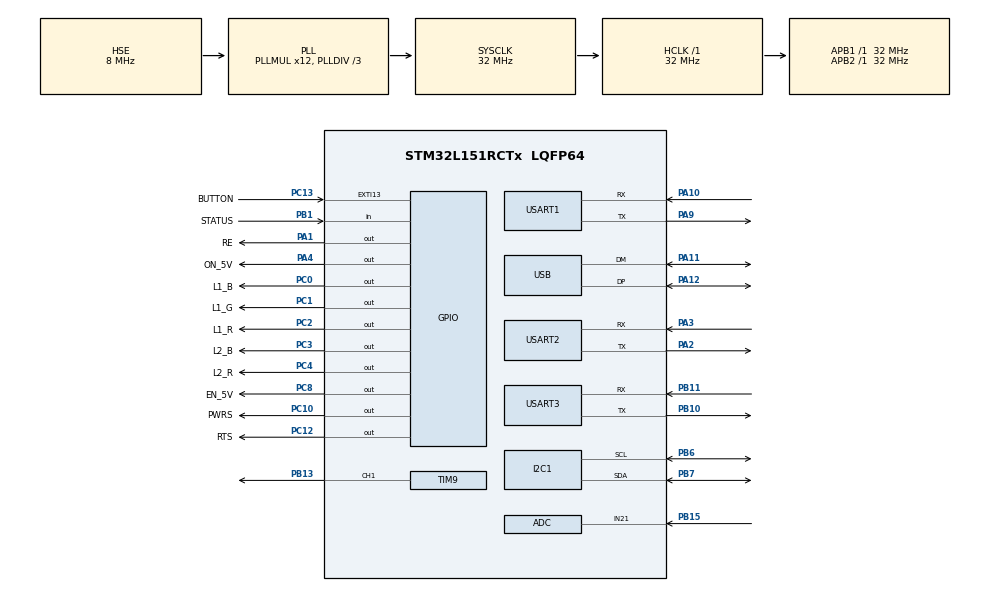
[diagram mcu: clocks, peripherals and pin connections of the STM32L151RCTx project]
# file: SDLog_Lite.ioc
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ADC.Channel-0\#ChannelRegularConversion=ADC_CHANNEL_21
ADC.NbrOfConversionFlag=1
ADC.Rank-0\#ChannelRegularConversion=1
ADC.SamplingTime-0\#ChannelRegularConversion=ADC_SAMPLETIME_4CYCLES
Dma.Request0=USART2_RX
Dma.Request1=USART3_RX
Dma.Request2=USART1_RX
Dma.USART1_RX.2.Direction=DMA_PERIPH_TO_MEMORY
Dma.USART1_RX.2.Instance=DMA1_Channel5
Dma.USART1_RX.2.MemDataAlignment=DMA_MDATAALIGN_BYTE
Dma.USART1_RX.2.MemInc=DMA_MINC_ENABLE
Dma.USART1_RX.2.Mode=DMA_NORMAL
Dma.USART1_RX.2.PeriphDataAlignment=DMA_PDATAALIGN_BYTE
Dma.USART1_RX.2.PeriphInc=DMA_PINC_DISABLE
Dma.USART1_RX.2.Priority=DMA_PRIORITY_LOW
Dma.USART2_RX.0.Direction=DMA_PERIPH_TO_MEMORY
Dma.USART2_RX.0.Instance=DMA1_Channel6
Dma.USART2_RX.0.MemDataAlignment=DMA_MDATAALIGN_BYTE
Dma.USART2_RX.0.MemInc=DMA_MINC_ENABLE
Dma.USART2_RX.0.Mode=DMA_NORMAL
Dma.USART2_RX.0.PeriphDataAlignment=DMA_PDATAALIGN_BYTE
Dma.USART2_RX.0.PeriphInc=DMA_PINC_DISABLE
Dma.USART2_RX.0.Priority=DMA_PRIORITY_LOW
Dma.USART3_RX.1.Direction=DMA_PERIPH_TO_MEMORY
Dma.USART3_RX.1.Instance=DMA1_Channel3
Dma.USART3_RX.1.MemDataAlignment=DMA_MDATAALIGN_BYTE
Dma.USART3_RX.1.MemInc=DMA_MINC_ENABLE
Dma.USART3_RX.1.Mode=DMA_NORMAL
Dma.USART3_RX.1.PeriphDataAlignment=DMA_PDATAALIGN_BYTE
Dma.USART3_RX.1.PeriphInc=DMA_PINC_DISABLE
Dma.USART3_RX.1.Priority=DMA_PRIORITY_LOW
Mcu.Family=STM32L1
Mcu.Name=STM32L151RCTx
Mcu.Package=LQFP64
NVIC.DMA1_Channel3_IRQn=true\:0\:0\:false\:false\:true\:false\:true\:true
NVIC.DMA1_Channel5_IRQn=true\:0\:0\:false\:false\:true\:false\:true\:true
NVIC.DMA1_Channel6_IRQn=true\:0\:0\:false\:false\:true\:false\:true\:true
NVIC.EXTI15_10_IRQn=true\:0\:0\:false\:false\:true\:true\:true\:true
NVIC.PriorityGroup=NVIC_PRIORITYGROUP_4
NVIC.RTC_Alarm_IRQn=true\:0\:0\:false\:false\:true\:true\:true\:true
NVIC.USART1_IRQn=true\:0\:0\:false\:false\:true\:true\:true\:true
NVIC.USART2_IRQn=true\:0\:0\:false\:false\:true\:true\:true\:true
NVIC.USART3_IRQn=true\:0\:0\:false\:false\:true\:true\:true\:true
NVIC.USB_LP_IRQn=true\:15\:0\:true\:false\:true\:false\:true\:true
PA1.GPIO_Label=RE
PA1.Signal=GPIO_Output
PA10.Mode=Asynchronous
PA10.Signal=USART1_RX
PA11.Mode=Device
PA11.Signal=USB_DM
PA12.Mode=Device
PA12.Signal=USB_DP
PA13.Mode=Trace_Asynchronous_SW
PA13.Signal=SYS_JTMS-SWDIO
PA14.Mode=Trace_Asynchronous_SW
PA14.Signal=SYS_JTCK-SWCLK
PA2.Mode=Asynchronous
PA2.Signal=USART2_TX
PA3.Mode=Asynchronous
PA3.Signal=USART2_RX
PA4.GPIO_Label=ON_5V
PA4.Signal=GPIO_Output
PA9.Mode=Asynchronous
PA9.Signal=USART1_TX
PB1.GPIO_Label=STATUS
PB1.GPIO_PuPd=GPIO_PULLDOWN
PB1.Signal=GPIO_Input
PB10.Mode=Asynchronous
PB10.Signal=USART3_TX
PB11.Mode=Asynchronous
PB11.Signal=USART3_RX
PB13.Signal=S_TIM9_CH1
PB15.Mode=IN21
PB15.Signal=ADC_IN21
PB3.Mode=Trace_Asynchronous_SW
PB3.Signal=SYS_JTDO-TRACESWO
PB6.Mode=I2C
PB6.Signal=I2C1_SCL
PB7.Mode=I2C
PB7.Signal=I2C1_SDA
PC0.GPIO_Label=L1_B
PC0.PinState=GPIO_PIN_SET
PC0.Signal=GPIO_Output
PC1.GPIO_Label=L1_G
PC1.PinState=GPIO_PIN_SET
PC1.Signal=GPIO_Output
PC10.GPIO_Label=PWRS
PC10.Signal=GPIO_Output
PC12.GPIO_Label=RTS
PC12.Signal=GPIO_Output
PC13-WKUP2.GPIO_Label=BUTTON
PC13-WKUP2.GPIO_ModeDefaultEXTI=GPIO_MODE_IT_RISING_FALLING
PC13-WKUP2.Signal=GPXTI13
PC14-OSC32_IN.Mode=LSE-External-Oscillator
PC14-OSC32_IN.Signal=RCC_OSC32_IN
PC15-OSC32_OUT.Mode=LSE-External-Oscillator
PC15-OSC32_OUT.Signal=RCC_OSC32_OUT
PC2.GPIO_Label=L1_R
PC2.PinState=GPIO_PIN_SET
PC2.Signal=GPIO_Output
PC3.GPIO_Label=L2_B
PC3.PinState=GPIO_PIN_SET
PC3.Signal=GPIO_Output
PC4.GPIO_Label=L2_R
PC4.PinState=GPIO_PIN_SET
PC4.Signal=GPIO_Output
PC8.GPIO_Label=EN_5V
PC8.Signal=GPIO_Output
PH0-OSC_IN.Mode=HSE-External-Oscillator
PH0-OSC_IN.Signal=RCC_OSC_IN
PH1-OSC_OUT.Mode=HSE-External-Oscillator
PH1-OSC_OUT.Signal=RCC_OSC_OUT
ProjectManager.HeapSize=0x800
ProjectManager.StackSize=0x1000
ProjectManager.TargetToolchain=Makefile
RCC.48MHZClocksFreq_Value=48000000
RCC.AHBFreq_Value=32000000
RCC.APB1Freq_Value=32000000
RCC.APB1TimFreq_Value=32000000
RCC.APB2Freq_Value=32000000
RCC.APB2TimFreq_Value=32000000
RCC.HCLKFreq_Value=32000000
RCC.HSE_VALUE=8000000
RCC.HSI_VALUE=16000000
RCC.MSI_VALUE=2097000
RCC.PLLDIV=RCC_PLL_DIV3
RCC.PLLMUL=RCC_PLL_MUL12
RCC.SYSCLKFreq_VALUE=32000000
RCC.SYSCLKSource=RCC_SYSCLKSOURCE_PLLCLK
RCC.VCOOutputFreq_Value=96000000
RTC.Alarm-Alarm\ A=RTC_ALARM_A
RTC.AlarmMaskDateWeekDay-Alarm\ A=RTC_ALARMMASK_DATEWEEKDAY
RTC.AlarmMaskHours-Alarm\ A=RTC_ALARMMASK_HOURS
RTC.AlarmMaskMinutes-Alarm\ A=RTC_ALARMMASK_MINUTES
RTC.AlarmMaskSeconds-Alarm\ A=RTC_ALARMMASK_SECONDS
RTC.Date=27
RTC.Hours=16
RTC.Minutes=32
RTC.Month=RTC_MONTH_FEBRUARY
RTC.Seconds=14
RTC.WeekDay=RTC_WEEKDAY_FRIDAY
RTC.Year=26
SH.S_TIM9_CH1.0=TIM9_CH1,PWM Generation1 CH1
TIM9.Channel-PWM\ Generation1\ CH1=TIM_CHANNEL_1
TIM9.Period=370-1
TIM9.Prescaler=32-1
USART1.VirtualMode=VM_ASYNC
USART2.VirtualMode=VM_ASYNC
USART3.VirtualMode=VM_ASYNC
USB_DEVICE.CLASS_NAME_FS=CDC
USB_DEVICE.MANUFACTURER_STRING=Smart Solutions System
USB_DEVICE.PRODUCT_STRING_CDC_FS=SDLog_Lite
USB_DEVICE.VirtualMode=Cdc
USB_DEVICE.VirtualModeFS=Cdc_FS
VP_RTC_VS_RTC_Activate.Mode=RTC_Enabled
VP_RTC_VS_RTC_Alarm_A_Intern.Mode=Alarm A
VP_RTC_VS_RTC_Calendar.Mode=RTC_Calendar
VP_TIM9_VS_ClockSourceINT.Mode=Internal
VP_USB_DEVICE_VS_USB_DEVICE_CDC_FS.Mode=CDC_FS
board=custom

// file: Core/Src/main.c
/* USER CODE BEGIN Header */
/**
 ******************************************************************************
 * @file           : main.c
 * @brief          : Main program body
 ******************************************************************************
 * @attention
 *
 * Copyright (c) 2026 STMicroelectronics.
 * All rights reserved.
 *
 * This software is licensed under terms that can be found in the LICENSE file
 * in the root directory of this software component.
 * If no LICENSE file comes with this software, it is provided AS-IS.
 *
 ******************************************************************************
 */
/* USER CODE END Header */
#include "main.h"
#include "adc.h"
#include "dma.h"
#include "i2c.h"
#include "rtc.h"
#include "tim.h"
#include "usart.h"
#include "usb_device.h"
#include "gpio.h"

/* USER CODE BEGIN Includes */
#include "application.h"
/* USER CODE END Includes */

void SystemClock_Config(void);

int main(void)
{

  /* MCU Configuration--------------------------------------------------------*/

  /* Reset of all peripherals, Initializes the Flash interface and the Systick. */
  HAL_Init();

  /* Configure the system clock */
  SystemClock_Config();

  /* Initialize all configured peripherals */
  MX_GPIO_Init();
  MX_DMA_Init();
  MX_ADC_Init();
  MX_USART2_UART_Init();
  MX_USART3_UART_Init();
  MX_I2C1_Init();
  MX_RTC_Init();
  MX_TIM9_Init();
  MX_USB_DEVICE_Init();
  MX_USART1_UART_Init();
  /* USER CODE BEGIN 2 */
  application_init();
  application_run();
  /* USER CODE END 2 */

  /* Infinite loop */
  while (1)
  {

  }
}

void SystemClock_Config(void)
{
  RCC_OscInitTypeDef RCC_OscInitStruct = {0};
  RCC_ClkInitTypeDef RCC_ClkInitStruct = {0};
  RCC_PeriphCLKInitTypeDef PeriphClkInit = {0};

  /** Configure the main internal regulator output voltage
  */
  __HAL_PWR_VOLTAGESCALING_CONFIG(PWR_REGULATOR_VOLTAGE_SCALE1);

  /** Initializes the RCC Oscillators according to the specified parameters
  * in the RCC_OscInitTypeDef structure.
  */
  RCC_OscInitStruct.OscillatorType = RCC_OSCILLATORTYPE_HSI|RCC_OSCILLATORTYPE_LSI
                              |RCC_OSCILLATORTYPE_HSE;
  RCC_OscInitStruct.HSEState = RCC_HSE_ON;
  RCC_OscInitStruct.HSIState = RCC_HSI_ON;
  RCC_OscInitStruct.HSICalibrationValue = RCC_HSICALIBRATION_DEFAULT;
  RCC_OscInitStruct.LSIState = RCC_LSI_ON;
  RCC_OscInitStruct.PLL.PLLState = RCC_PLL_ON;
  RCC_OscInitStruct.PLL.PLLSource = RCC_PLLSOURCE_HSE;
  RCC_OscInitStruct.PLL.PLLMUL = RCC_PLL_MUL12;
  RCC_OscInitStruct.PLL.PLLDIV = RCC_PLL_DIV3;
  if (HAL_RCC_OscConfig(&RCC_OscInitStruct) != HAL_OK)
  {
    Error_Handler();
  }

  /** Initializes the CPU, AHB and APB buses clocks
  */
  RCC_ClkInitStruct.ClockType = RCC_CLOCKTYPE_HCLK|RCC_CLOCKTYPE_SYSCLK
                              |RCC_CLOCKTYPE_PCLK1|RCC_CLOCKTYPE_PCLK2;
  RCC_ClkInitStruct.SYSCLKSource = RCC_SYSCLKSOURCE_PLLCLK;
  RCC_ClkInitStruct.AHBCLKDivider = RCC_SYSCLK_DIV1;
  RCC_ClkInitStruct.APB1CLKDivider = RCC_HCLK_DIV1;
  RCC_ClkInitStruct.APB2CLKDivider = RCC_HCLK_DIV1;

  if (HAL_RCC_ClockConfig(&RCC_ClkInitStruct, FLASH_LATENCY_1) != HAL_OK)
  {
    Error_Handler();
  }
  PeriphClkInit.PeriphClockSelection = RCC_PERIPHCLK_RTC;
  PeriphClkInit.RTCClockSelection = RCC_RTCCLKSOURCE_LSI;
  if (HAL_RCCEx_PeriphCLKConfig(&PeriphClkInit) != HAL_OK)
  {
    Error_Handler();
  }
}

void Error_Handler(void)
{
  __disable_irq();
  while (1)
  {
  }
}
